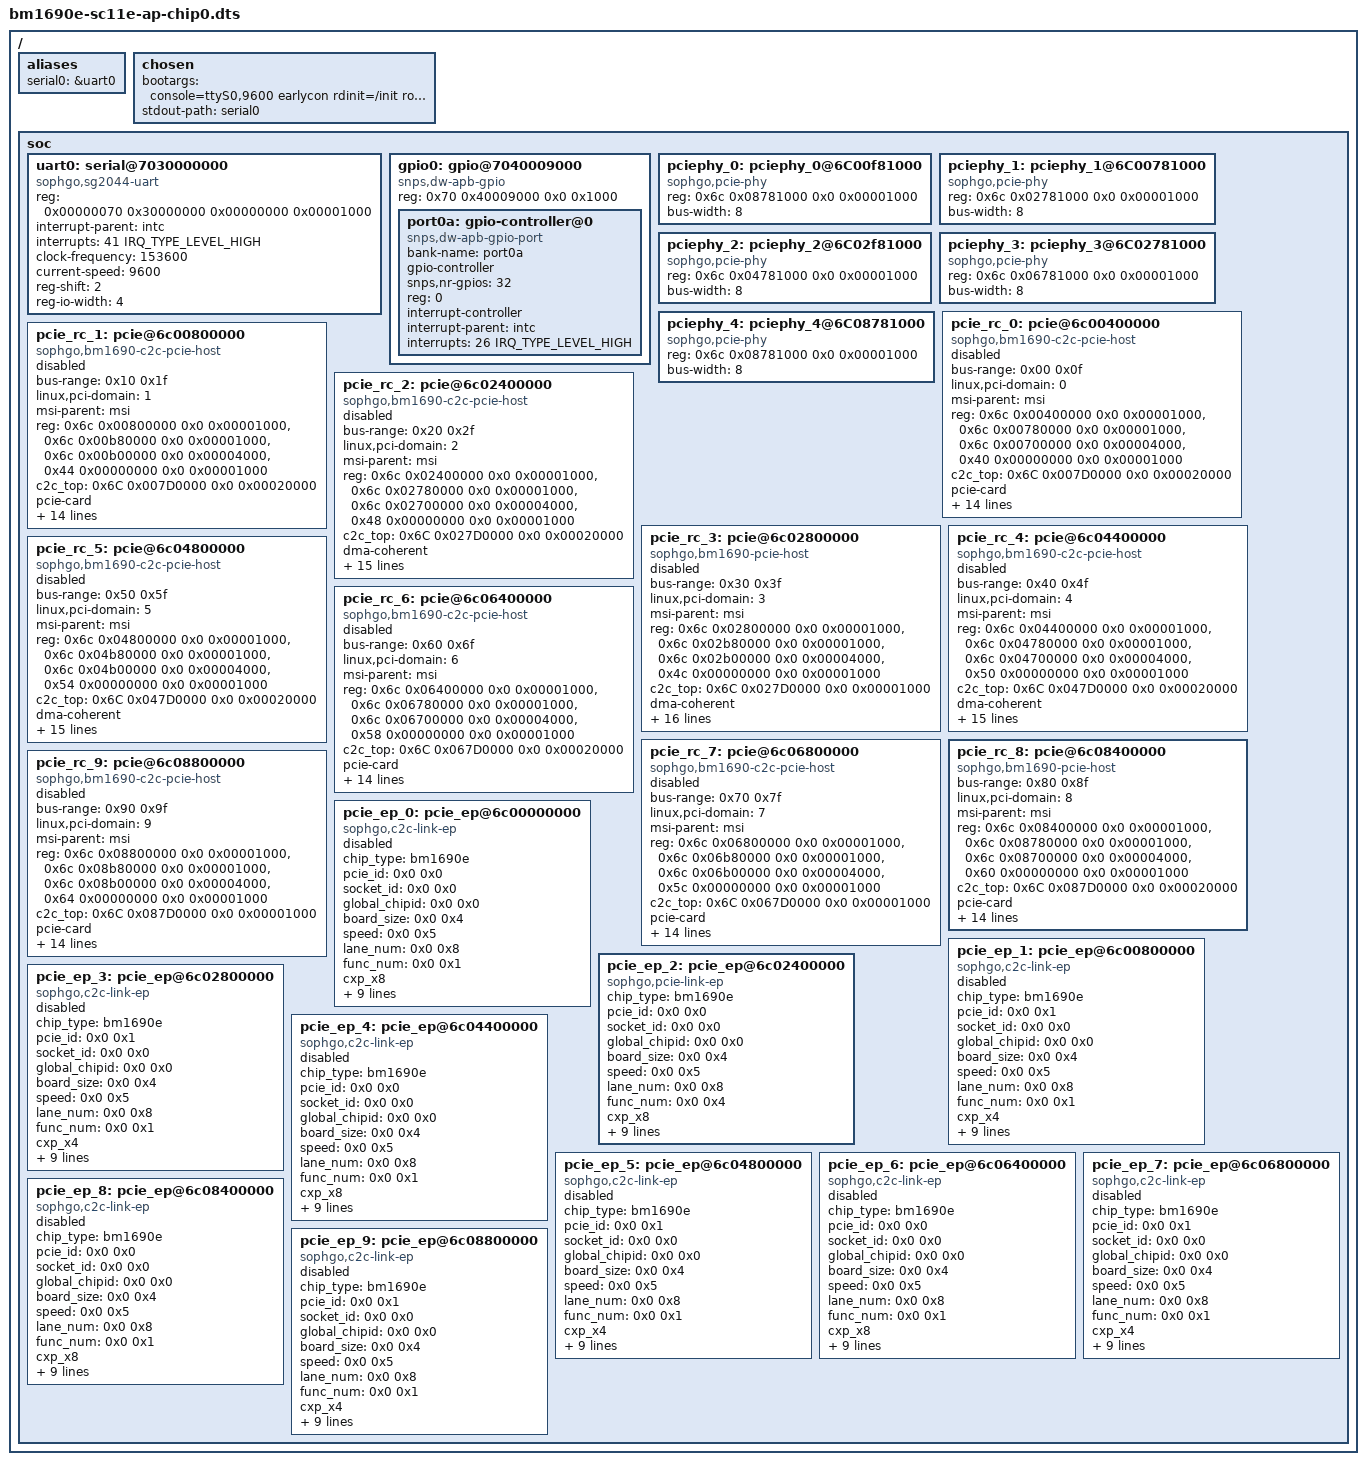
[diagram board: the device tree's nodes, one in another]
// SPDX-License-Identifier: (GPL-2.0 OR MIT)
/*
 * Copyright (C) 2022 Sophgo Technology Inc. All rights reserved.
 */

/dts-v1/;
#include <dt-bindings/interrupt-controller/irq.h>
#include "bm1690-cpu-ap.dtsi"
#include "bm1690-pcie-msi.dtsi"

/ {
	aliases {
		serial0 = &uart0;
	};

	chosen {
		bootargs = "console=ttyS0,9600 earlycon rdinit=/init root=/dev/ram0 rw initrd=0x8b000000,32M maxcpus=4";
		stdout-path = "serial0";
	};

	soc {
		uart0: serial@7030000000 {
			compatible = "sophgo,sg2044-uart", "snps,dw-apb-uart";
			reg = <0x00000070 0x30000000 0x00000000 0x00001000>;
			interrupt-parent = <&intc>;
			interrupts = <41 IRQ_TYPE_LEVEL_HIGH>;
			clock-frequency = <153600>;
			current-speed = <9600>;
			reg-shift = <2>;
			reg-io-width = <4>;
		};

		gpio0: gpio@7040009000 {
			compatible = "snps,dw-apb-gpio";
			reg = <0x70 0x40009000 0x0 0x1000>;
			#address-cells = <1>;
			#size-cells = <0>;
			//clocks = <&div_clk GATE_CLK_APB_GPIO>,
			//		<&div_clk GATE_CLK_APB_GPIO_INTR>,
			//		<&div_clk GATE_CLK_GPIO_DB>;
			//clock-names = "base_clk", "intr_clk", "db_clk";

			port0a: gpio-controller@0 {
				compatible = "snps,dw-apb-gpio-port";
				bank-name = "port0a";
				gpio-controller;
				#gpio-cells = <2>;
				snps,nr-gpios = <32>;
				reg = <0>;
				interrupt-controller;
				#interrupt-cells = <2>;
				interrupt-parent = <&intc>;
				interrupts = <26 IRQ_TYPE_LEVEL_HIGH>;
			};
		};


		//c2c0 x8/x4
		pciephy_0: pciephy_0@6C00f81000 {
			compatible = "sophgo,pcie-phy";
			#phy-cells = <1>;
			reg = <0x6c 0x08781000 0x0 0x00001000>;
			bus-width = <8>;
		};

		//c2c1 x8/x4
		pciephy_1: pciephy_1@6C00781000 {
			compatible = "sophgo,pcie-phy";
			#phy-cells = <1>;
			reg = <0x6c 0x02781000 0x0 0x00001000>;
			bus-width = <8>;
		};

		//c2c2 x8/x4
		pciephy_2: pciephy_2@6C02f81000 {
			compatible = "sophgo,pcie-phy";
			#phy-cells = <1>;
			reg = <0x6c 0x04781000 0x0 0x00001000>;
			bus-width = <8>;
		};

		//c2c3 x8/x4
		pciephy_3: pciephy_3@6C02781000 {
			compatible = "sophgo,pcie-phy";
			#phy-cells = <1>;
			reg = <0x6c 0x06781000 0x0 0x00001000>;
			bus-width = <8>;
		};

		//c2c4 x8/x4
		pciephy_4: pciephy_4@6C08781000 {
			compatible = "sophgo,pcie-phy";
			#phy-cells = <1>;
			reg = <0x6c 0x08781000 0x0 0x00001000>;
			bus-width = <8>;
		};

		//c2c0_x8
		pcie_rc_0: pcie@6c00400000 {
			compatible = "sophgo,bm1690-c2c-pcie-host";
			device_type = "pci";
			#address-cells = <3>;
			#size-cells = <2>;

			bus-range = <0x00 0x0f>;
			linux,pci-domain = <0>;
			msi-parent = <&msi>;
			reg = <0x6c 0x00400000  0x0 0x00001000>,
			      <0x6c 0x00780000  0x0 0x00001000>,
			      <0x6c 0x00700000  0x0 0x00004000>,
			      <0x40 0x00000000  0x0 0x00001000>;
			reg-names = "dbi", "ctrl_base", "atu", "config";
			c2c_top =  <0x6C 0x007D0000  0x0 0x00020000>;
			pcie-card;
			cxp_x8;

			phys = <&pciephy_0 0>;
			phy-names = "pcie-phy";

			max-link-speed = <4>;
			num-lanes = <8>;

			prst = <&port0a 17 0>;

			// IO, check IO_SPACE_LIMIT
			// 32bit prefetchable memory
			// 32bit non-prefetchable memory
			// 64bit prefetchable memory
			// 64bit non-prefetchable memory

			ranges = <0x01000000 0x0  0x00000000  0x40 0x10000000  0x0 0x00400000>,
				 <0x42000000 0x0  0x20000000  0x40  0x20000000  0x0 0x04000000>,
				 <0x02000000 0x0  0x24000000  0x40  0x24000000  0x0 0x04000000>,
				 <0x43000000 0x41 0x00000000  0x41 0x00000000  0x2 0x00000000>,
				 <0x03000000 0x43 0x00000000  0x43 0x00000000  0x1 0x00000000>;
			dma-ranges = <0x03000000 0x0 0x0 0x0 0x0 0x40 0x0>,
				     <0x43000000 0x40 0x0 0x40 0x0 0x40 0x0>;
			cfg_range = <0x6c 0x00000000 0x6c 0x01ffffff>;
			slv_range = <0x40 0x00000000 0x43 0xffffffff>;
			cdma-reg = <0x6b 0x007a0000 0x0 0x10000>;

			socket_id = <0x0 0x0>;
			global_chipid = <0x0 0x0>;
			board_size = <0x0 0x4>;

			status = "disable";
		};

		//c2c0_x4
		pcie_rc_1: pcie@6c00800000 {
			compatible = "sophgo,bm1690-c2c-pcie-host";
			device_type = "pci";
			#address-cells = <3>;
			#size-cells = <2>;

			bus-range = <0x10 0x1f>;
			linux,pci-domain = <1>;
			msi-parent = <&msi>;
			reg = <0x6c 0x00800000  0x0 0x00001000>,
			      <0x6c 0x00b80000 0x0 0x00001000>,
			      <0x6c 0x00b00000  0x0 0x00004000>,
			      <0x44 0x00000000  0x0 0x00001000>;
			reg-names = "dbi", "ctrl_base", "atu", "config";
			c2c_top =  <0x6C 0x007D0000  0x0 0x00020000>;
			pcie-card;
			cxp_x4;

			phys = <&pciephy_0 1>;
			phy-names = "pcie-phy";

			max-link-speed = <4>;
			num-lanes = <8>;

			prst = <&port0a 18 0>;

			// IO, check IO_SPACE_LIMIT
			// 32bit prefetchable memory
			// 32bit non-prefetchable memory
			// 64bit prefetchable memory
			// 64bit non-prefetchable memory

			ranges = <0x01000000 0x0  0x00000000  0x44 0x10000000  0x0 0x00400000>,
				 <0x42000000 0x0  0x20000000  0x44  0x20000000  0x0 0x04000000>,
				 <0x02000000 0x0  0x24000000  0x44  0x24000000  0x0 0x04000000>,
				 <0x43000000 0x45 0x00000000  0x45 0x00000000  0x2 0x00000000>,
				 <0x03000000 0x47 0x00000000  0x47 0x00000000  0x1 0x00000000>;
			dma-ranges = <0x03000000 0x0 0x0 0x0 0x0 0x40 0x0>,
				     <0x43000000 0x40 0x0 0x40 0x0 0x40 0x0>;

			cfg_range = <0x6c 0x00000000 0x6c 0x01ffffff>;
			slv_range = <0x44 0x00000000 0x47 0xffffffff>;
			cdma-reg = <0x6b 0x007b0000 0x0 0x10000>;

			socket_id = <0x0 0x0>;
			global_chipid = <0x0 0x0>;
			board_size = <0x0 0x4>;

			status = "disable";
		};

		//c2c1_x8
		pcie_rc_2: pcie@6c02400000 {
			compatible = "sophgo,bm1690-c2c-pcie-host";
			device_type = "pci";
			#address-cells = <3>;
			#size-cells = <2>;

			bus-range = <0x20 0x2f>;
			linux,pci-domain = <2>;
			msi-parent = <&msi>;
			reg = <0x6c 0x02400000  0x0 0x00001000>,
			      <0x6c 0x02780000  0x0 0x00001000>,
			      <0x6c 0x02700000  0x0 0x00004000>,
			      <0x48 0x00000000  0x0 0x00001000>;
			reg-names = "dbi", "ctrl_base", "atu", "config";
			c2c_top = <0x6C 0x027D0000  0x0 0x00020000>;
			dma-coherent;
			pcie-card;
			cxp_x8;

			phys = <&pciephy_1 0>;
			phy-names = "pcie-phy";

			max-link-speed = <4>;
			num-lanes = <8>;

			prst = <&port0a 19 0>;

			// IO, check IO_SPACE_LIMIT
			// 32bit prefetchable memory
			// 32bit non-prefetchable memory
			// 64bit prefetchable memory
			// 64bit non-prefetchable memory

			ranges = <0x01000000 0x0  0x00000000  0x48 0x10000000  0x0 0x00400000>,
				 <0x42000000 0x0  0x20000000  0x48  0x20000000  0x0 0x04000000>,
				 <0x02000000 0x0  0x24000000  0x48  0x24000000  0x0 0x04000000>,
				 <0x43000000 0x49 0x00000000  0x49 0x00000000  0x2 0x00000000>,
				 <0x03000000 0x4b 0x00000000  0x4b 0x00000000  0x1 0x00000000>;
			dma-ranges = <0x03000000 0x0 0x0 0x0 0x0 0x40 0x0>,
				     <0x43000000 0x40 0x0 0x40 0x0 0x40 0x0>;
			cfg_range = <0x6c 0x02000000 0x6c 0x03ffffff>;
			slv_range = <0x48 0x00000000 0x4b 0xffffffff>;
			cdma-reg = <0x6b 0x027a0000 0x0 0x10000>;

			socket_id = <0x0 0x0>;
			global_chipid = <0x0 0x0>;
			board_size = <0x0 0x4>;

			status = "disable";
		};

		//c2c1_x4
		pcie_rc_3: pcie@6c02800000 {
			compatible = "sophgo,bm1690-pcie-host";
			device_type = "pci";
			#address-cells = <3>;
			#size-cells = <2>;

			bus-range = <0x30 0x3f>;
			linux,pci-domain = <3>;
			msi-parent = <&msi>;
			reg = <0x6c 0x02800000  0x0 0x00001000>,
			      <0x6c 0x02b80000 0x0 0x00001000>,
			      <0x6c 0x02b00000  0x0 0x00004000>,
			      <0x4c 0x00000000  0x0 0x00001000>;
			reg-names = "dbi", "ctrl_base", "atu", "config";
			c2c_top = <0x6C 0x027D0000  0x0 0x00001000>;
			dma-coherent;
			pcie-card;
			cxp_x4;

			phys = <&pciephy_1 0>;
			phy-names = "pcie-phy";

			max-link-speed = <4>;
			num-lanes = <8>;

			prst = <&port0a 20 0>;

			// IO, check IO_SPACE_LIMIT
			// 32bit prefetchable memory
			// 32bit non-prefetchable memory
			// 64bit prefetchable memory
			// 64bit non-prefetchable memory

			ranges = <0x01000000 0x0  0x00000000  0x4c 0x10000000  0x0 0x00400000>,
				 <0x42000000 0x0  0x20000000  0x4c  0x20000000  0x0 0x04000000>,
				 <0x02000000 0x0  0x24000000  0x4c  0x24000000  0x0 0x04000000>,
				 <0x43000000 0x4a 0x00000000  0x4a 0x00000000  0x2 0x00000000>,
				 <0x03000000 0x4c 0x00000000  0x4c 0x00000000  0x1 0x00000000>;
			dma-ranges = <0x03000000 0x0 0x0 0x0 0x0 0x40 0x0>,
				     <0x43000000 0x40 0x0 0x40 0x0 0x40 0x0>;
			cfg_range = <0x6c 0x02000000 0x6c 0x03ffffff>;
			slv_range = <0x4c 0x00000000 0x4f 0xffffffff>;
			cdma-reg = <0x6b 0x027b0000 0x0 0x10000>;

			socket_id = <0x0 0x0>;
			global_chipid = <0x0 0x0>;
			board_size = <0x0 0x4>;
			dst-chip = <0x2>;

			status = "disable";
		};

		//c2c2_x8
		pcie_rc_4: pcie@6c04400000 {
			compatible = "sophgo,bm1690-c2c-pcie-host";
			device_type = "pci";
			#address-cells = <3>;
			#size-cells = <2>;

			bus-range = <0x40 0x4f>;
			linux,pci-domain = <4>;
			msi-parent = <&msi>;
			reg = <0x6c 0x04400000  0x0 0x00001000>,
			      <0x6c 0x04780000  0x0 0x00001000>,
			      <0x6c 0x04700000  0x0 0x00004000>,
			      <0x50 0x00000000  0x0 0x00001000>;
			reg-names = "dbi", "ctrl_base", "atu", "config";
			c2c_top = <0x6C 0x047D0000  0x0 0x00020000>;
			dma-coherent;
			pcie-card;
			cxp_x8;

			phys = <&pciephy_2 0>;
			phy-names = "pcie-phy";

			max-link-speed = <4>;
			num-lanes = <8>;

			prst = <&port0a 21 0>;

			// IO, check IO_SPACE_LIMIT
			// 32bit prefetchable memory
			// 32bit non-prefetchable memory
			// 64bit prefetchable memory
			// 64bit non-prefetchable memory

			ranges = <0x01000000 0x0  0x00000000  0x50 0x10000000  0x0 0x00400000>,
				 <0x42000000 0x0  0x20000000  0x50 0x20000000  0x0 0x04000000>,
				 <0x02000000 0x0  0x24000000  0x50 0x24000000  0x0 0x04000000>,
				 <0x43000000 0x51 0x00000000  0x51 0x00000000  0x2 0x00000000>,
				 <0x03000000 0x53 0x00000000  0x53 0x00000000  0x1 0x00000000>;
			dma-ranges = <0x03000000 0x0 0x0 0x0 0x0 0x40 0x0>,
				     <0x43000000 0x40 0x0 0x40 0x0 0x40 0x0>;
			cfg_range = <0x6c 0x04000000 0x6c 0x05ffffff>;
			slv_range = <0x50 0x00000000 0x53 0xffffffff>;
			cdma-reg = <0x6b 0x047a0000 0x0 0x10000>;

			socket_id = <0x0 0x0>;
			global_chipid = <0x0 0x0>;
			board_size = <0x0 0x4>;

			status = "disable";
		};

		//c2c2_x4
		pcie_rc_5: pcie@6c04800000 {
			compatible = "sophgo,bm1690-c2c-pcie-host";
			device_type = "pci";
			#address-cells = <3>;
			#size-cells = <2>;

			bus-range = <0x50 0x5f>;
			linux,pci-domain = <5>;
			msi-parent = <&msi>;
			reg = <0x6c 0x04800000  0x0 0x00001000>,
			      <0x6c 0x04b80000  0x0 0x00001000>,
			      <0x6c 0x04b00000  0x0 0x00004000>,
			      <0x54 0x00000000  0x0 0x00001000>;
			reg-names = "dbi", "ctrl_base", "atu", "config";
			c2c_top = <0x6C 0x047D0000  0x0 0x00020000>;
			dma-coherent;
			pcie-card;
			cxp_x4;

			phys = <&pciephy_2 1>;
			phy-names = "pcie-phy";

			max-link-speed = <4>;
			num-lanes = <8>;

			prst = <&port0a 22 0>;

			// IO, check IO_SPACE_LIMIT
			// 32bit prefetchable memory
			// 32bit non-prefetchable memory
			// 64bit prefetchable memory
			// 64bit non-prefetchable memory

			ranges = <0x01000000 0x0  0x00000000  0x54 0x10000000  0x0 0x00400000>,
				 <0x42000000 0x0  0x20000000  0x54 0x20000000  0x0 0x04000000>,
				 <0x02000000 0x0  0x24000000  0x54 0x24000000  0x0 0x04000000>,
				 <0x43000000 0x55 0x00000000  0x55 0x00000000  0x2 0x00000000>,
				 <0x03000000 0x57 0x00000000  0x57 0x00000000  0x1 0x00000000>;
			dma-ranges = <0x03000000 0x0 0x0 0x0 0x0 0x40 0x0>,
				     <0x43000000 0x40 0x0 0x40 0x0 0x40 0x0>;
			cfg_range = <0x6c 0x04000000 0x6c 0x05ffffff>;
			slv_range = <0x54 0x00000000 0x57 0xffffffff>;
			cdma-reg = <0x6b 0x047b0000 0x0 0x10000>;

			socket_id = <0x0 0x0>;
			global_chipid = <0x0 0x0>;
			board_size = <0x0 0x4>;

			status = "disable";
		};

		//c2c3_x8
		pcie_rc_6: pcie@6c06400000 {
			compatible = "sophgo,bm1690-c2c-pcie-host";
			device_type = "pci";
			#address-cells = <3>;
			#size-cells = <2>;

			bus-range = <0x60 0x6f>;
			linux,pci-domain = <6>;
			msi-parent = <&msi>;
			reg = <0x6c 0x06400000  0x0 0x00001000>,
			      <0x6c 0x06780000  0x0 0x00001000>,
			      <0x6c 0x06700000  0x0 0x00004000>,
			      <0x58 0x00000000  0x0 0x00001000>;
			reg-names = "dbi", "ctrl_base", "atu", "config";
			c2c_top = <0x6C 0x067D0000  0x0 0x00020000>;
			pcie-card;
			cxp_x8;

			phys = <&pciephy_3 0>;
			phy-names = "pcie-phy";

			max-link-speed = <4>;
			num-lanes = <8>;

			prst = <&port0a 23 0>;

			// IO, check IO_SPACE_LIMIT
			// 32bit prefetchable memory
			// 32bit non-prefetchable memory
			// 64bit prefetchable memory
			// 64bit non-prefetchable memory

			ranges = <0x01000000 0x0  0x00000000  0x58 0x10000000  0x0 0x00400000>,
				 <0x42000000 0x0  0x20000000  0x58 0x20000000  0x0 0x04000000>,
				 <0x02000000 0x0  0x24000000  0x58 0x24000000  0x0 0x04000000>,
				 <0x43000000 0x59 0x00000000  0x59 0x00000000  0x2 0x00000000>,
				 <0x03000000 0x5b 0x00000000  0x5b 0x00000000  0x1 0x00000000>;
			dma-ranges = <0x03000000 0x0 0x0 0x0 0x0 0x40 0x0>,
				     <0x43000000 0x40 0x0 0x40 0x0 0x40 0x0>;
			cfg_range = <0x6c 0x06000000 0x6c 0x07ffffff>;
			slv_range = <0x58 0x00000000 0x5b 0xffffffff>;
			cdma-reg = <0x6b 0x067a0000 0x0 0x10000>;

			socket_id = <0x0 0x0>;
			global_chipid = <0x0 0x0>;
			board_size = <0x0 0x4>;

			status = "disable";
		};

		//c2c3_x4
		pcie_rc_7: pcie@6c06800000 {
			compatible = "sophgo,bm1690-c2c-pcie-host";
			device_type = "pci";
			#address-cells = <3>;
			#size-cells = <2>;

			bus-range = <0x70 0x7f>;
			linux,pci-domain = <7>;
			msi-parent = <&msi>;
			reg = <0x6c 0x06800000  0x0 0x00001000>,
			      <0x6c 0x06b80000  0x0 0x00001000>,
			      <0x6c 0x06b00000  0x0 0x00004000>,
			      <0x5c 0x00000000  0x0 0x00001000>;
			reg-names = "dbi", "ctrl_base", "atu", "config";
			c2c_top = <0x6C 0x067D0000  0x0 0x00001000>;
			pcie-card;
			cxp_x4;

			phys = <&pciephy_3 1>;
			phy-names = "pcie-phy";

			max-link-speed = <4>;
			num-lanes = <8>;

			prst = <&port0a 24 0>;

			// IO, check IO_SPACE_LIMIT
			// 32bit prefetchable memory
			// 32bit non-prefetchable memory
			// 64bit prefetchable memory
			// 64bit non-prefetchable memory

			ranges = <0x01000000 0x0  0x00000000  0x5c 0x10000000  0x0 0x00400000>,
				 <0x42000000 0x0  0x20000000  0x5c 0x20000000  0x0 0x04000000>,
				 <0x02000000 0x0  0x24000000  0x5c 0x24000000  0x0 0x04000000>,
				 <0x43000000 0x5d 0x00000000  0x5d 0x00000000  0x2 0x00000000>,
				 <0x03000000 0x5f 0x00000000  0x5f 0x00000000  0x1 0x00000000>;
			dma-ranges = <0x03000000 0x0 0x0 0x0 0x0 0x40 0x0>,
				     <0x43000000 0x40 0x0 0x40 0x0 0x40 0x0>;
			cfg_range = <0x6c 0x06000000 0x6c 0x07ffffff>;
			slv_range = <0x5c 0x00000000 0x5f 0xffffffff>;
			cdma-reg = <0x6b 0x067b0000 0x0 0x10000>;

			socket_id = <0x0 0x0>;
			global_chipid = <0x0 0x0>;
			board_size = <0x0 0x4>;

			status = "disable";
		};

		//c2c4_x8 cascade rc
		pcie_rc_8: pcie@6c08400000 {
			compatible = "sophgo,bm1690-pcie-host";
			device_type = "pci";
			#address-cells = <3>;
			#size-cells = <2>;

			bus-range = <0x80 0x8f>;
			linux,pci-domain = <8>;
			msi-parent = <&msi>;
			reg = <0x6c 0x08400000  0x0 0x00001000>,
			      <0x6c 0x08780000  0x0 0x00001000>,
			      <0x6c 0x08700000  0x0 0x00004000>,
			      <0x60 0x00000000  0x0 0x00001000>;
			reg-names = "dbi", "ctrl_base", "atu", "config";
			c2c_top = <0x6C 0x087D0000  0x0 0x00020000>;
			pcie-card;
			cxp_x8;

			phys = <&pciephy_4 0>;
			phy-names = "pcie-phy";

			max-link-speed = <4>;
			num-lanes = <8>;

			prst = <&port0a 25 0>;

			// IO, check IO_SPACE_LIMIT
			// 32bit prefetchable memory
			// 32bit non-prefetchable memory
			// 64bit prefetchable memory
			// 64bit non-prefetchable memory

			ranges = <0x01000000 0x0  0x00000000  0x60 0x10000000  0x0 0x00400000>,
				 <0x42000000 0x0  0x20000000  0x60 0x20000000  0x0 0x04000000>,
				 <0x02000000 0x0  0x24000000  0x60 0x24000000  0x0 0x10000000>,
				 <0x43000000 0x20000 0x00000000  0x20000 0x00000000  0x20000 0x00000000>,
				 <0x03000000 0x63 0x00000000  0x63 0x00000000  0x1 0x00000000>;
			dma-ranges = <0x03000000 0x0 0x0 0x0 0x0 0x40 0x0>,
				     <0x43000000 0x40 0x0 0x40 0x0 0x40 0x0>;
			cfg_range = <0x6c 0x08000000 0x6c 0x09ffffff>;
			slv_range = <0x60 0x00000000 0x63 0xffffffff>;
			cdma-reg = <0x6b 0x087a0000 0x0 0x10000>;

			socket_id = <0x0 0x0>;
			global_chipid = <0x0 0x0>;
			board_size = <0x0 0x4>;

			status = "okay";
		};

		//c2c4_x4
		pcie_rc_9: pcie@6c08800000 {
			compatible = "sophgo,bm1690-c2c-pcie-host";
			device_type = "pci";
			#address-cells = <3>;
			#size-cells = <2>;

			bus-range = <0x90 0x9f>;
			linux,pci-domain = <9>;
			msi-parent = <&msi>;
			reg = <0x6c 0x08800000  0x0 0x00001000>,
			      <0x6c 0x08b80000  0x0 0x00001000>,
			      <0x6c 0x08b00000  0x0 0x00004000>,
			      <0x64 0x00000000  0x0 0x00001000>;
			reg-names = "dbi", "ctrl_base", "atu", "config";
			c2c_top = <0x6C 0x087D0000  0x0 0x00001000>;
			pcie-card;
			cxp_x4;

			phys = <&pciephy_4 1>;
			phy-names = "pcie-phy";

			max-link-speed = <4>;
			num-lanes = <8>;

			prst = <&port0a 26 0>;

			// IO, check IO_SPACE_LIMIT
			// 32bit prefetchable memory
			// 32bit non-prefetchable memory
			// 64bit prefetchable memory
			// 64bit non-prefetchable memory

			ranges = <0x01000000 0x0  0x00000000  0x64 0x10000000  0x0 0x00400000>,
				 <0x42000000 0x0  0x20000000  0x64 0x20000000  0x0 0x04000000>,
				 <0x02000000 0x0  0x24000000  0x64 0x24000000  0x0 0x04000000>,
				 <0x43000000 0x65 0x00000000  0x65 0x00000000  0x2 0x00000000>,
				 <0x03000000 0x67 0x00000000  0x67 0x00000000  0x1 0x00000000>;
			dma-ranges = <0x03000000 0x0 0x0 0x0 0x0 0x40 0x0>,
				     <0x43000000 0x40 0x0 0x40 0x0 0x40 0x0>;
			cfg_range = <0x6c 0x08000000 0x6c 0x09ffffff>;
			slv_range = <0x64 0x00000000 0x67 0xffffffff>;
			cdma-reg = <0x6b 0x087b0000 0x0 0x10000>;

			socket_id = <0x0 0x0>;
			global_chipid = <0x0 0x0>;
			board_size = <0x0 0x4>;

			status = "disable";
		};

		//c2c0_x8
		pcie_ep_0: pcie_ep@6c00000000 {
			compatible = "sophgo,c2c-link-ep";
			chip_type = "bm1690e";
			#address-cells = <2>;
			#size-cells = <2>;
			ranges;//this is must, must, must, must
			pcie_id = <0x0 0x0>;
			socket_id = <0x0 0x0>;
			global_chipid = <0x0 0x0>;
			board_size = <0x0 0x4>;
			speed = <0x0 0x5>;
			lane_num = <0x0 0x8>;
			func_num = <0x0 0x1>;
			cxp_x8;

			reg =	<0x6c 0x00400000  0x0 0x00300000>,
				<0x6c 0x00700000  0x0 0x00004000>,
				<0x6c 0x00780000  0x0 0x00001000>;
			reg-names = "dbi", "atu", "ctrl";

			c2c_config_range = <0x6c 0x00000000 0x00000000 0x01ffffff>;
			c2c_top = <0x6c 0x007d0000  0x0 0x00002000>;
			cdma-reg = <0x6c 0x007b0000 0x0 0x10000>;

			phys = <&pciephy_0 0>;
			phy-names = "pcie-phy";

			perst-gpios = <&port0a 17 0>;

			status = "disable";
		};

		//c2c0_x4
		pcie_ep_1: pcie_ep@6c00800000 {
			compatible = "sophgo,c2c-link-ep";
			chip_type = "bm1690e";
			#address-cells = <2>;
			#size-cells = <2>;
			ranges;//this is must, must, must, must
			pcie_id = <0x0 0x1>;
			socket_id = <0x0 0x0>;
			global_chipid = <0x0 0x0>;
			board_size = <0x0 0x4>;
			speed = <0x0 0x5>;
			lane_num = <0x0 0x8>;
			func_num = <0x0 0x1>;
			cxp_x4;

			reg =   <0x6c 0x00800000 0x00000000 0x00300000>,
				<0x6c 0x00b00000 0x00000000 0x00004000>,
				<0x6c 0x00b80000 0x00000000 0x00001000>;
			reg-names = "dbi", "atu", "ctrl";

			c2c_config_range = <0x6c 0x00000000 0x00000000 0x01ffffff>;
			c2c_top = <0x6c 0x007d0000  0x0 0x00002000>;
			cdma-reg = <0x6c 0x00790000 0x0 0x10000>;

			phys = <&pciephy_0 1>;
			phy-names = "pcie-phy";

			perst-gpios = <&port0a 18 0>;

			status = "disable";
		};

		//c2c1_x8
		pcie_ep_2: pcie_ep@6c02400000 {
			compatible = "sophgo,pcie-link-ep";
			chip_type = "bm1690e";
			#address-cells = <2>;
			#size-cells = <2>;
			ranges;//this is must, must, must, must
			pcie_id = <0x0 0x0>;
			socket_id = <0x0 0x0>;
			global_chipid = <0x0 0x0>;
			board_size = <0x0 0x4>;
			speed = <0x0 0x5>;
			lane_num = <0x0 0x8>;
			func_num = <0x0 0x4>;
			cxp_x8;

			reg =	<0x6c 0x02400000  0x0 0x00300000>,
				<0x6c 0x02700000  0x0 0x00004000>,
				<0x6c 0x02780000  0x0 0x00001000>;
			reg-names = "dbi", "atu", "ctrl";

			c2c_config_range = <0x6c 0x02000000 0x00000000 0x01ffffff>;
			c2c_top = <0x6c 0x027d0000  0x0 0x00002000>;
			cdma-reg = <0x6b 0x027a0000 0x0 0x10000>;

			phys = <&pciephy_1 0>;
			phy-names = "pcie-phy";

			perst-gpios = <&port0a 19 0>;

			status = "okay";
		};

		//c2c1_x4
		pcie_ep_3: pcie_ep@6c02800000 {
			compatible = "sophgo,c2c-link-ep";
			chip_type = "bm1690e";
			#address-cells = <2>;
			#size-cells = <2>;
			ranges;//this is must, must, must, must
			pcie_id = <0x0 0x1>;
			socket_id = <0x0 0x0>;
			global_chipid = <0x0 0x0>;
			board_size = <0x0 0x4>;
			speed = <0x0 0x5>;
			lane_num = <0x0 0x8>;
			func_num = <0x0 0x1>;
			cxp_x4;

			reg =   <0x6c 0x02800000 0x00000000 0x00300000>,
				<0x6c 0x02b00000 0x00000000 0x00004000>,
				<0x6c 0x02b80000 0x00000000 0x00001000>;
			reg-names = "dbi", "atu", "ctrl";

			c2c_config_range = <0x6c 0x02000000 0x00000000 0x01ffffff>;
			c2c_top = <0x6c 0x027d0000  0x0 0x00002000>;
			cdma-reg = <0x6b 0x027b0000 0x0 0x10000>;

			phys = <&pciephy_1 1>;
			phy-names = "pcie-phy";

			perst-gpios = <&port0a 20 0>;

			status = "disable";
		};

		//c2c2_x8
		pcie_ep_4: pcie_ep@6c04400000 {
			compatible = "sophgo,c2c-link-ep";
			chip_type = "bm1690e";
			#address-cells = <2>;
			#size-cells = <2>;
			ranges;//this is must, must, must, must
			pcie_id = <0x0 0x0>;
			socket_id = <0x0 0x0>;
			global_chipid = <0x0 0x0>;
			board_size = <0x0 0x4>;
			speed = <0x0 0x5>;
			lane_num = <0x0 0x8>;
			func_num = <0x0 0x1>;
			cxp_x8;

			reg =	<0x6c 0x04400000  0x0 0x00300000>,
				<0x6c 0x04700000  0x0 0x00004000>,
				<0x6c 0x04780000  0x0 0x00001000>;
			reg-names = "dbi", "atu", "ctrl";

			c2c_config_range = <0x6c 0x04000000 0x00000000 0x01ffffff>;
			c2c_top = <0x6c 0x047d0000  0x0 0x00002000>;
			cdma-reg = <0x6b 0x047b0000 0x0 0x10000>;

			phys = <&pciephy_2 0>;
			phy-names = "pcie-phy";

			perst-gpios = <&port0a 21 0>;

			status = "disable";
		};

		//c2c2_x4
		pcie_ep_5: pcie_ep@6c04800000 {
			compatible = "sophgo,c2c-link-ep";
			chip_type = "bm1690e";
			#address-cells = <2>;
			#size-cells = <2>;
			ranges;//this is must, must, must, must
			pcie_id = <0x0 0x1>;
			socket_id = <0x0 0x0>;
			global_chipid = <0x0 0x0>;
			board_size = <0x0 0x4>;
			speed = <0x0 0x5>;
			lane_num = <0x0 0x8>;
			func_num = <0x0 0x1>;
			cxp_x4;

			reg =   <0x6c 0x04800000 0x00000000 0x00300000>,
				<0x6c 0x04b00000 0x00000000 0x00004000>,
				<0x6c 0x04b80000 0x00000000 0x00001000>;
			reg-names = "dbi", "atu", "ctrl";

			c2c_config_range = <0x6c 0x04000000 0x00000000 0x01ffffff>;
			c2c_top = <0x6c 0x047d0000  0x0 0x00002000>;
			cdma-reg = <0x6c 0x047b0000 0x0 0x10000>;

			phys = <&pciephy_2 1>;
			phy-names = "pcie-phy";

			perst-gpios = <&port0a 22 0>;

			status = "disable";
		};

		//c2c3_x8
		pcie_ep_6: pcie_ep@6c06400000 {
			compatible = "sophgo,c2c-link-ep";
			chip_type = "bm1690e";
			#address-cells = <2>;
			#size-cells = <2>;
			ranges;//this is must, must, must, must
			pcie_id = <0x0 0x0>;
			socket_id = <0x0 0x0>;
			global_chipid = <0x0 0x0>;
			board_size = <0x0 0x4>;
			speed = <0x0 0x5>;
			lane_num = <0x0 0x8>;
			func_num = <0x0 0x1>;
			cxp_x8;

			reg =	<0x6c 0x06400000  0x0 0x00300000>,
				<0x6c 0x06700000  0x0 0x00004000>,
				<0x6c 0x06780000  0x0 0x00001000>;
			reg-names = "dbi", "atu", "ctrl";

			c2c_config_range = <0x6c 0x06000000 0x00000000 0x01ffffff>;
			c2c_top = <0x6c 0x067d0000  0x0 0x00002000>;
			cdma-reg = <0x6b 0x067a0000 0x0 0x10000>;

			phys = <&pciephy_3 0>;
			phy-names = "pcie-phy";

			perst-gpios = <&port0a 23 0>;

			status = "disable";
		};

		//c2c3_x4
		pcie_ep_7: pcie_ep@6c06800000 {
			compatible = "sophgo,c2c-link-ep";
			chip_type = "bm1690e";
			#address-cells = <2>;
			#size-cells = <2>;
			ranges;//this is must, must, must, must
			pcie_id = <0x0 0x1>;
			socket_id = <0x0 0x0>;
			global_chipid = <0x0 0x0>;
			board_size = <0x0 0x4>;
			speed = <0x0 0x5>;
			lane_num = <0x0 0x8>;
			func_num = <0x0 0x1>;
			cxp_x4;

			reg =   <0x6c 0x06800000 0x00000000 0x00300000>,
				<0x6c 0x06b00000 0x00000000 0x00004000>,
				<0x6c 0x06b80000 0x00000000 0x00001000>;
			reg-names = "dbi", "atu", "ctrl";

			c2c_config_range = <0x6c 0x06000000 0x00000000 0x01ffffff>;
			c2c_top = <0x6c 0x067d0000  0x0 0x00002000>;
			cdma-reg = <0x6b 0x067b0000 0x0 0x10000>;

			phys = <&pciephy_3 1>;
			phy-names = "pcie-phy";

			perst-gpios = <&port0a 24 0>;

			status = "disable";
		};

		//c2c4_x8
		pcie_ep_8: pcie_ep@6c08400000 {
			compatible = "sophgo,c2c-link-ep";
			chip_type = "bm1690e";
			#address-cells = <2>;
			#size-cells = <2>;
			ranges;//this is must, must, must, must
			pcie_id = <0x0 0x0>;
			socket_id = <0x0 0x0>;
			global_chipid = <0x0 0x0>;
			board_size = <0x0 0x4>;
			speed = <0x0 0x5>;
			lane_num = <0x0 0x8>;
			func_num = <0x0 0x1>;
			cxp_x8;

			reg =	<0x6c 0x08400000  0x0 0x00300000>,
				<0x6c 0x08700000  0x0 0x00004000>,
				<0x6c 0x08780000  0x0 0x00001000>;
			reg-names = "dbi", "atu", "ctrl";

			c2c_config_range = <0x6c 0x08000000 0x00000000 0x01ffffff>;
			c2c_top = <0x6c 0x087d0000  0x0 0x00002000>;
			cdma-reg = <0x6b 0x087a0000 0x0 0x10000>;

			phys = <&pciephy_4 0>;
			phy-names = "pcie-phy";

			perst-gpios = <&port0a 25 0>;

			status = "disable";
		};

		//c2c4_x4
		pcie_ep_9: pcie_ep@6c08800000 {
			compatible = "sophgo,c2c-link-ep";
			chip_type = "bm1690e";
			#address-cells = <2>;
			#size-cells = <2>;
			ranges;//this is must, must, must, must
			pcie_id = <0x0 0x1>;
			socket_id = <0x0 0x0>;
			global_chipid = <0x0 0x0>;
			board_size = <0x0 0x4>;
			speed = <0x0 0x5>;
			lane_num = <0x0 0x8>;
			func_num = <0x0 0x1>;
			cxp_x4;

			reg =   <0x6c 0x08800000 0x00000000 0x00300000>,
				<0x6c 0x08b00000 0x00000000 0x00004000>,
				<0x6c 0x08b80000 0x00000000 0x00001000>;
			reg-names = "dbi", "atu", "ctrl";

			c2c_config_range = <0x6c 0x08000000 0x00000000 0x01ffffff>;
			c2c_top = <0x6c 0x087d0000  0x0 0x00002000>;
			cdma-reg = <0x6b 0x087b0000 0x0 0x10000>;

			phys = <&pciephy_4 1>;
			phy-names = "pcie-phy";

			perst-gpios = <&port0a 26 0>;

			status = "disable";
		};
	};

};

